# PIC12LF1552 register map
Vendor: Microchip
Registers are 8-bit, read-write, reset 0x0 unless marked. A register's access mark holds for its fields unless they carry their own. Addresses are absolute, and some are shared; only a register's first bit layout is shown; [hi:lo] are bit positions; {n}, {i} and the like mark numbered series.

## SFR
0x00 INDF0 reset not defined — (power-on value xxxxxxxx)
0x01 INDF1 reset not defined — (power-on value xxxxxxxx)
0x02 PCL
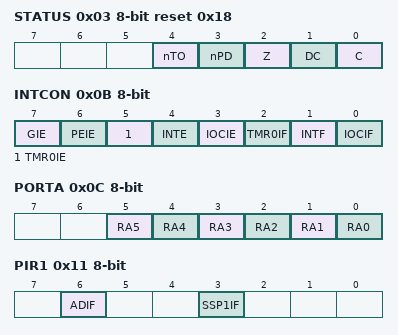
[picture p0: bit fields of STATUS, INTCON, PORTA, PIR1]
0x03 STATUS reset 0x18
  [4] nTO ro, [3] nPD ro, [2] Z, [1] DC, [0] C
0x04 FSR0L
0x05 FSR0H
0x06 FSR1L
0x07 FSR1H
0x08 BSR
  [4:0] BSR
0x09 WREG
  [7:0] WREG0
0x0A PCLATH
  [6:0] PCLATH
0x0B INTCON
  [7] GIE, [6] PEIE, [5] TMR0IE, [4] INTE, [3] IOCIE, [2] TMR0IF, [1] INTF, [0] IOCIF ro
0x0C PORTA reset not defined — (power-on value --xxxxxx)
  [5] RA5, [4] RA4, [3] RA3 ro, [2] RA2, [1] RA1, [0] RA0
0x11 PIR1
  [6] ADIF — A/D Converter Interrupt Flag bit
  [3] SSP1IF — Master Synchronous Serial Port (MSSP) Interrupt Flag bit
0x12 PIR2
  [3] BCL1IF — MSSP Bus Collision Interrupt Flag bit
0x15 TMR0 reset not defined — (power-on value xxxxxxxx)
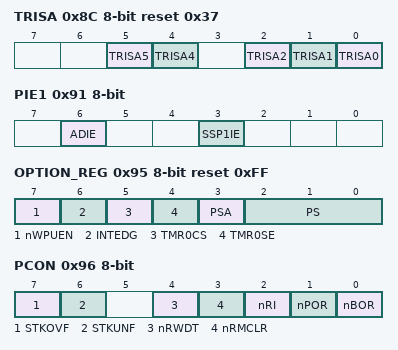
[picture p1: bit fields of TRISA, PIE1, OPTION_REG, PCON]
0x8C TRISA reset 0x37 — PORTA Data Direction Control Register
  [5] TRISA5, [4] TRISA4, [2] TRISA2, [1] TRISA1, [0] TRISA0
0x91 PIE1 — Peripheral Interrupt Enable Register 1
  [6] ADIE — A/D Converter Interrupt Enable bit
  [3] SSP1IE — Master Synchronous Serial Port (MSSP) Interrupt Enable bit
0x92 PIE2 — Peripheral Interrupt Enable Register 2
  [3] BCL1IE — MSSP Bus Collision Interrupt Enable bit
0x95 OPTION_REG reset 0xFF — Option Register
  [7] nWPUEN — Weak Pull-up Enable bit
  [6] INTEDG — Interrupt Edge Select bit
  [5] TMR0CS — TMR0 Clock Source Select bit
  [4] TMR0SE — TMR0 Source Edge Select bit
  [3] PSA — Prescaler Active bit
  [2:0] PS — Prescaler Rate Select bits
0x96 PCON reset not defined — Power Control Register (power-on value 00-111qq)
  [7] STKOVF — Stack Overflow Flag bit
  [6] STKUNF — Stack Underflow Flag bit
  [4] nRWDT
  [3] nRMCLR — MCLR Reset Flag bit
  [2] nRI — RESET Instruction Flag bit
  [1] nPOR — Power-on Reset Status bit
  [0] nBOR — Brown-out Reset Status bit
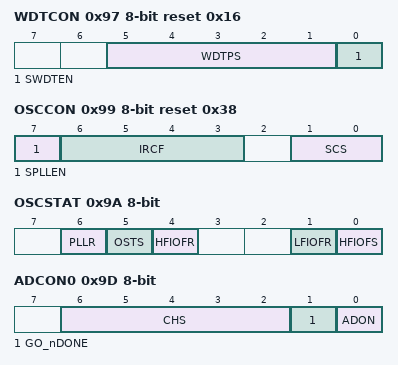
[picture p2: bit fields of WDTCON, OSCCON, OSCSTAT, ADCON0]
0x97 WDTCON reset 0x16 — Watchdog Timer Control Register
  [5:1] WDTPS — Watchdog Timer Period Select bits
  [0] SWDTEN — Software Enable/Disable for Watch Dog Timer bit
0x99 OSCCON reset 0x38 — Oscillator Control Register
  [7] SPLLEN — Software PLL Enable bit
  [6:3] IRCF — Internal Oscillator Frequency Select bits
  [1:0] SCS — System clock select bit
0x9A OSCSTAT reset not defined — Oscillator Status Register (power-on value -0q0--00)
  [6] PLLR — 4x PLL Ready bit
  [5] OSTS — Oscillator Start-up Time-out Status bit
  [4] HFIOFR — High Freqency Internal Oscillator Ready bit
  [1] LFIOFR — Low Freqency Internal Oscillator Ready bit
  [0] HFIOFS — Low Freqency Internal Oscillator Ready bit
0x9B ADRESL reset not defined — A/D Result Register LSB (power-on value xxxxxxxx)
0x9C ADRESH reset not defined — A/D Result Register MSB (power-on value xxxxxxxx)
0x9D ADCON0 — Analog-to-Digital Control Register 0
  [6:2] CHS — Analog Channel Select bits
  [1] GO_nDONE — A/D Conversion Status bit
  [0] ADON — A/D Module Enable bit
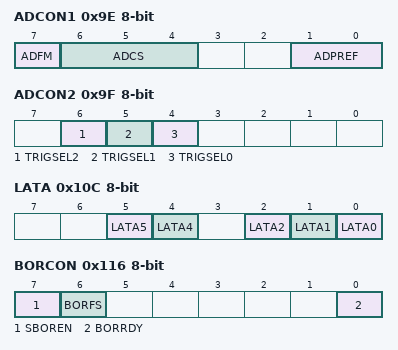
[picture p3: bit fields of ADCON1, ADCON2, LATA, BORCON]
0x9E ADCON1 — Analog-to-Digital Control Register 1
  [7] ADFM — A/D Result Format Select bit
  [6:4] ADCS — A/D Conversion Clock Select bits
  [1:0] ADPREF — A/D Positive Voltage Reference Configuration
0x9F ADCON2
  [6] TRIGSEL2 — A/D Conversion Trigger Selection bits
  [5] TRIGSEL1 — A/D Conversion Trigger Selection bits
  [4] TRIGSEL0 — A/D Conversion Trigger Selection bits
0x10C LATA reset not defined — (power-on value --xx-xxx)
  [5] LATA5, [4] LATA4, [2] LATA2, [1] LATA1, [0] LATA0
0x116 BORCON reset not defined — Brown-out Reset Control Register (power-on value 10-----q)
  [7] SBOREN — Software Brown Out Reset Enable bit
  [6] BORFS
  [0] BORRDY ro — Brown-out Reset Circuit Ready Status bit
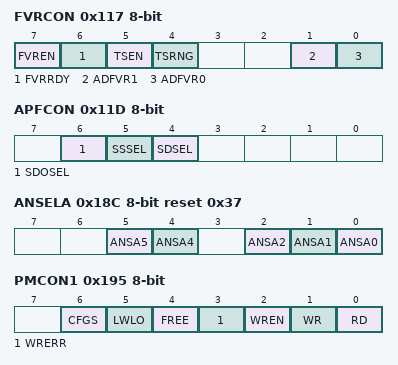
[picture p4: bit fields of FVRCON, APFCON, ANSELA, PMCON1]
0x117 FVRCON reset not defined — Fixed Voltage Reference Control Register (power-on value 0q00--00)
  [7] FVREN — Fixed Voltage Reference Enable
  [6] FVRRDY ro — Fixed Voltage Reference Ready Flag
  [5] TSEN
  [4] TSRNG
  [1] ADFVR1 — A/D Converter Fixed Voltage Reference Selection
  [0] ADFVR0 — A/D Converter Fixed Voltage Reference Selection
0x11D APFCON — Alternate Pin Function Control Register
  [6] SDOSEL — SDO Pin Selection
  [5] SSSEL — SS Pin Selection
  [4] SDSEL
0x18C ANSELA reset 0x37
  [5] ANSA5, [4] ANSA4, [2] ANSA2, [1] ANSA1, [0] ANSA0
0x191 PMADRL
0x192 PMADRH reset 0x80
  [6:0] PMADRH
0x193 PMDATL reset not defined — (power-on value xxxxxxxx)
0x194 PMDATH reset not defined — (power-on value --xxxxxx)
  [5:0] PMDATH
0x195 PMCON1 reset not defined — Program Memory Control Register 1 (power-on value 1000x000)
  [6] CFGS — FLASH Program / Data EEPROM or Configuration Select bit
  [5] LWLO — Load Write Latches Only bit
  [4] FREE — Program FLASH Erase Enable bit
  [3] WRERR — Sequence Error Flag bit
  [2] WREN — Program/Erase Enable bit
  [1] WR — Write Control bit (can only be set)
  [0] RD — Read Control bit (can only be set)
0x196 PMCON2 wo — Program Memory Control Register 2
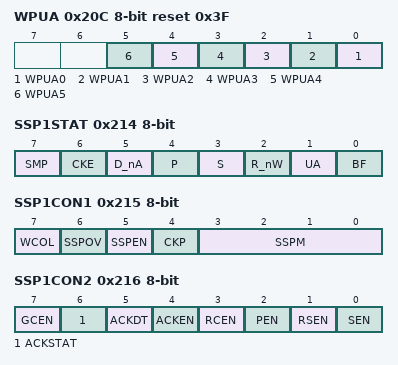
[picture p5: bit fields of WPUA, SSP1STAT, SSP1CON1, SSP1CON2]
0x20C WPUA reset 0x3F
  [n] WPUA{n} (n=0..5)
0x211 SSP1BUF reset not defined — (power-on value xxxxxxxx)
  [7:0] SSPBUF
0x212 SSP1ADD
  [7:0] SSPADD
0x213 SSP1MSK reset 0xFF
  [7:0] SSPMSK
0x214 SSP1STAT
  [7] SMP, [6] CKE, [5] D_nA ro, [4] P ro, [3] S ro, [2] R_nW ro, [1] UA ro, [0] BF ro
0x215 SSP1CON1 reset not defined — (power-on value 0000xxxx)
  [7] WCOL, [6] SSPOV, [5] SSPEN, [4] CKP, [3:0] SSPM
0x216 SSP1CON2
  [7] GCEN, [6] ACKSTAT ro, [5] ACKDT, [4] ACKEN, [3] RCEN, [2] PEN, [1] RSEN, [0] SEN
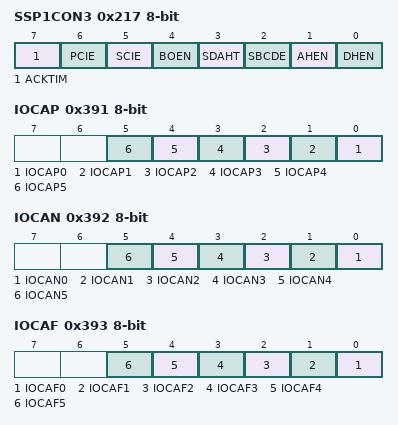
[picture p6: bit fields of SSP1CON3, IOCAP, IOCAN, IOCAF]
0x217 SSP1CON3
  [7] ACKTIM ro, [6] PCIE, [5] SCIE, [4] BOEN, [3] SDAHT, [2] SBCDE, [1] AHEN, [0] DHEN
0x391 IOCAP — Interrupt-On-Change Positive Edge Register
  [n] IOCAP{n} (n=0..5)
0x392 IOCAN — Interrupt-On-Change Negative Edge Register
  [n] IOCAN{n} (n=0..5)
0x393 IOCAF — Interrupt-On-Change Flag Register
  [n] IOCAF{n} (n=0..5)
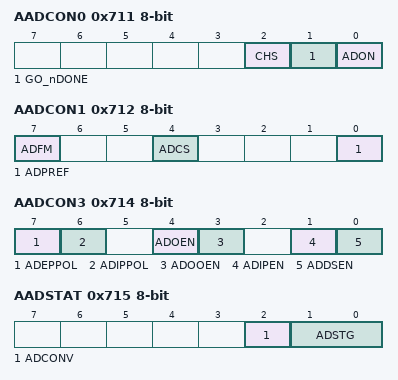
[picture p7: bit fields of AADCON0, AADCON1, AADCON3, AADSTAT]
0x711 AADCON0
  [2] CHS
  [1] GO_nDONE — A/D Conversion Status bit
  [0] ADON — A/D Module Enable bit
0x712 AADCON1
  [7] ADFM — A/D Result Format Select bit
  [4] ADCS — A/D Conversion Clock Select
  [0] ADPREF — A/D Positive Voltage Reference Configuration
0x713 AADCON2
  [6:4] TRIGSEL — A/D Auto Conversion Trigger Selection bits
0x714 AADCON3
  [7] ADEPPOL — External Precharge Polarity bit
  [6] ADIPPOL — Internal Precharge Polarity bit
  [4] ADOEN — ADOUT Output enable Bit
  [3] ADOOEN — ADOUT Override Enable Bit
  [1] ADIPEN — A/D Invert Polarity Enable Bit
  [0] ADDSEN — A/D Double Sample Enable bit
0x715 AADSTAT reset not defined — (power-on value -----0xx)
  [2] ADCONV ro — A/D Conversion Status Bit
  [1:0] ADSTG — A/D Stage Status Bit
0x716 AADPRE
  [6:0] ADPRE — A/D Precharge Time Select Bits
0x717 AADACQ
  [6:0] ADACQ — Acquisition/Charge Share Time Select Bits
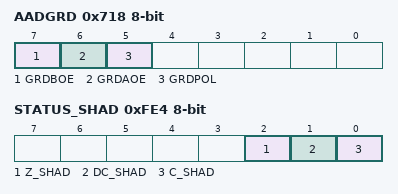
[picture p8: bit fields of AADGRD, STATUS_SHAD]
0x718 AADGRD
  [7] GRDBOE — Guard Ring B Output Enable
  [6] GRDAOE — Guard Ring A Output Enable
  [5] GRDPOL — Guard Ring Polarity selection bit
0x719 AADCAP
  [2:0] ADDCAP — ADC Additional Sample Capacitor Selection bits
0x71A AADRES0L reset not defined — (power-on value xxxxxxxx)
  [7:0] ADRES0L
0x71B AADRES0H reset not defined — (power-on value xxxxxxxx)
  [7:0] ADRES0H
0x71C AADRES1L reset not defined — (power-on value xxxxxxxx)
  [7:0] ADRES1L
0x71D AADRES1H reset not defined — (power-on value xxxxxxxx)
  [7:0] ADRES1H
0xFE4 STATUS_SHAD reset not defined — (power-on value -----xxx)
  [2] Z_SHAD, [1] DC_SHAD, [0] C_SHAD
0xFE5 WREG_SHAD reset not defined — (power-on value xxxxxxxx)
0xFE6 BSR_SHAD reset not defined — (power-on value ---xxxxx)
  [4:0] BSR_SHAD
0xFE7 PCLATH_SHAD reset not defined — (power-on value -xxxxxxx)
  [6:0] PCLATH_SHAD
0xFE8 FSR0L_SHAD reset not defined — (power-on value xxxxxxxx)
0xFE9 FSR0H_SHAD reset not defined — (power-on value xxxxxxxx)
0xFEA FSR1L_SHAD reset not defined — (power-on value xxxxxxxx)
0xFEB FSR1H_SHAD reset not defined — (power-on value xxxxxxxx)
0xFED STKPTR reset 0x1F — Current Stack pointer
  [4:0] STKPTR
0xFEE TOSL reset not defined — Top of Stack Low byte (power-on value xxxxxxxx)
0xFEF TOSH reset not defined — Top of Stack High byte (power-on value -xxxxxxx)
  [6:0] TOSH
